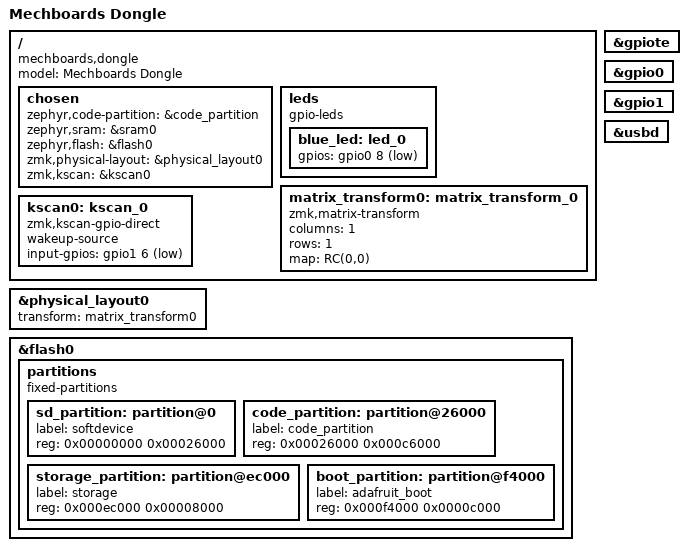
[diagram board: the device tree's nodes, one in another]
/*
 * Copyright (c) 2020 The ZMK Contributors
 *
 * SPDX-License-Identifier: MIT
 */

/dts-v1/;
#include <nordic/nrf52840_qiaa.dtsi>
#include <common/nordic/nrf52840_uf2_boot_mode.dtsi>
#include <dt-bindings/led/led.h>

#include <dt-bindings/zmk/matrix_transform.h>

#include "dongle-layouts.dtsi"

&physical_layout0 {
    transform = <&matrix_transform0>;
};

/ {
    model = "Mechboards Dongle";
    compatible = "mechboards,dongle";

    chosen {
        zephyr,code-partition = &code_partition;
        zephyr,sram = &sram0;
        zephyr,flash = &flash0;
        zmk,physical-layout = &physical_layout0;
        zmk,kscan = &kscan0;
    };

    leds {
        compatible = "gpio-leds";
        blue_led: led_0 {
            gpios = <&gpio0 8 GPIO_ACTIVE_LOW>;
        };
    };

    matrix_transform0: matrix_transform_0 {
        compatible = "zmk,matrix-transform";
        columns = <1>;
        rows = <1>;
        map = <
            RC(0,0)
        >;
    };

    kscan0: kscan_0 {
        compatible = "zmk,kscan-gpio-direct";
        wakeup-source;
        input-gpios
            = <&gpio1  6 (GPIO_ACTIVE_LOW | GPIO_PULL_UP)>
            ;
    };
};

&gpiote {
	status = "okay";
};

&gpio0 {
	status = "okay";
};

&gpio1 {
	status = "okay";
};

zephyr_udc0: &usbd {
    status = "okay";
};

&flash0 {
	/*
	 * For more information, see:
	 * http://docs.zephyrproject.org/latest/devices/dts/flash_partitions.html
	 */
	partitions {
		compatible = "fixed-partitions";
		#address-cells = <1>;
		#size-cells = <1>;

		sd_partition: partition@0 {
			label = "softdevice";
			reg = <0x00000000 0x00026000>;
		};
		code_partition: partition@26000 {
			label = "code_partition";
			reg = <0x00026000 0x000c6000>;
		};

		/*
		 * The flash starting at 0x000ec000 and ending at
		 * 0x000f3fff is reserved for use by the application.
		 */

		/*
		 * Storage partition will be used by FCB/LittleFS/NVS
		 * if enabled.
		 */
		storage_partition: partition@ec000 {
			label = "storage";
			reg = <0x000ec000 0x00008000>;
		};

		boot_partition: partition@f4000 {
			label = "adafruit_boot";
			reg = <0x000f4000 0x0000c000>;
		};
	};
};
